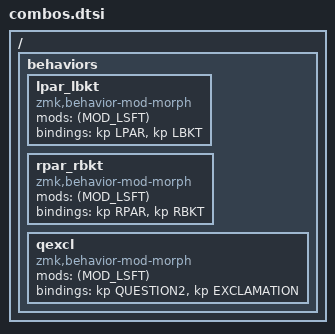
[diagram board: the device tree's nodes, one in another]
/*                                      46 KEY MATRIX / LAYOUT MAPPING
 ╭─────────────────────────╮               ╭─────────────────────────╮
 │ LT5 LT4 LT3 LT2 LT1 LT0 │               │ RT0 RT1 RT2 RT3 RT4 RT5 │
 │ LM5 LM4 LM3 LM2 LM1 LM0 ╰──╮         ╭──╯ RM0 RM1 RM2 RM3 RM4 RM5 │
 │ LB5 LB4 LB3 LB2 LB1 LB0 LH4╰────┬────╯RH4 RB0 RB1 RB2 RB3 RB4 RB5 │
 ╰───────────────╮ LH3 LH2 LH1 LH0 │ RH0 RH1 RH2 RH3 ╭───────────────╯
                 ╰─────────────────┴─────────────────╯
*/

#include "hillside46_key_labels.h"
#include "helpers.h"

#define COMBO_TERM_FAST 23
#define COMBO_TERM_SLOW 30

#define COMBO_IDLE_FAST 150
#define COMBO_IDLE_SLOW 50

#define DEF 0
#define NUM 1
#define SYM 2
#define ADJ 3

// unused keycode to workaround mapping keys to the same symbol simultaneously on ru qwerty and us querty
#define QUESTION2 INT3
#define COLON2 INT2


ZMK_MOD_MORPH(lpar_lbkt, mods = <(MOD_LSFT)>; bindings = <&kp LPAR>, <&kp LBKT>;)
ZMK_MOD_MORPH(rpar_rbkt, mods = <(MOD_LSFT)>; bindings = <&kp RPAR>, <&kp RBKT>;)
ZMK_MOD_MORPH(qexcl, mods = <(MOD_LSFT)>; bindings = <&kp QUESTION2>, <&kp EXCLAMATION>;)

ZMK_COMBO(lpar,  &lpar_lbkt,     RM1 RM2,     DEF NUM, COMBO_TERM_FAST, COMBO_IDLE_FAST)
ZMK_COMBO(rpar,  &rpar_rbkt,     RM2 RM3,     DEF NUM, COMBO_TERM_FAST, COMBO_IDLE_FAST)

ZMK_COMBO(lbrc,  &kp LBRC,     RB1 RB2,     DEF NUM, COMBO_TERM_FAST, COMBO_IDLE_FAST)
ZMK_COMBO(rbrc,  &kp RBRC,     RB2 RB3,     DEF NUM, COMBO_TERM_FAST, COMBO_IDLE_FAST)
ZMK_COMBO(bslh,  &kp BSLH,     RB3 RB4,     DEF, COMBO_TERM_FAST, COMBO_IDLE_FAST)

ZMK_COMBO(sqt,   &kp SQT,      RM3 RM4,     DEF NUM, COMBO_TERM_FAST, COMBO_IDLE_FAST)

ZMK_COMBO(qexcl,  &qexcl,      RT1 RT2,     DEF NUM, COMBO_TERM_FAST, COMBO_IDLE_FAST)
ZMK_COMBO(colon2, &kp COLON2,  RT2 RT3,     DEF NUM, COMBO_TERM_FAST, COMBO_IDLE_FAST)

ZMK_COMBO(pipe,     &kp PIPE,        RT1 RM1,     DEF NUM , COMBO_TERM_SLOW, COMBO_IDLE_SLOW)

// cyrillic х and ъ
ZMK_COMBO(cyrx,  &kp LBKT,     RT3 RT4,     DEF NUM , COMBO_TERM_FAST, COMBO_IDLE_FAST)
ZMK_COMBO(cyrb,  &kp RBKT,     RT4 RM4,     DEF NUM , COMBO_TERM_FAST, COMBO_IDLE_FAST)

// left hand

ZMK_COMBO(hash,   &kp HASH,      LM4 LM3,     DEF NUM , COMBO_TERM_FAST, COMBO_IDLE_FAST)
ZMK_COMBO(minus,  &kp MINUS,     LM3 LM2,     DEF NUM , COMBO_TERM_FAST, COMBO_IDLE_FAST)
ZMK_COMBO(equal,  &kp EQUAL,     LM2 LM1,     DEF NUM , COMBO_TERM_FAST, COMBO_IDLE_FAST)

ZMK_COMBO(star,   &kp ASTRK,     LT3 LT2,     DEF NUM , COMBO_TERM_FAST, COMBO_IDLE_FAST)
ZMK_COMBO(caret,  &kp CARET,     LT2 LT1,     DEF NUM , COMBO_TERM_FAST, COMBO_IDLE_FAST)

ZMK_COMBO(dollar, &kp DOLLAR,    LB2 LB1,     DEF NUM , COMBO_TERM_FAST, COMBO_IDLE_FAST)
ZMK_COMBO(amps,   &kp AMPS,      LB3 LB2,     DEF NUM , COMBO_TERM_FAST, COMBO_IDLE_FAST)

ZMK_COMBO(at,     &kp AT,        LM1 LB1,     DEF NUM , COMBO_TERM_SLOW, COMBO_IDLE_SLOW)
ZMK_COMBO(percent,&kp PERCENT,   LM2 LB2,     DEF NUM , COMBO_TERM_SLOW, COMBO_IDLE_SLOW)
